VERSION ""

NS_ :

BS_:

BU_: ECU1 ECU2 ECU3

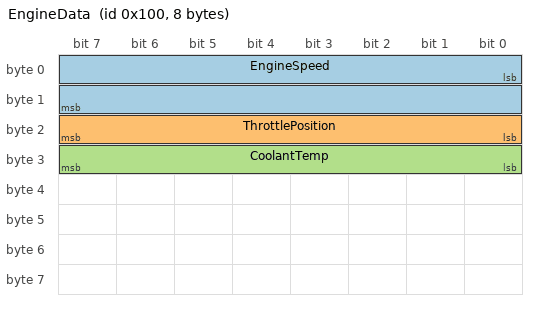
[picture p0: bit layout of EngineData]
BO_ 256 EngineData: 8 ECU1
 SG_ EngineSpeed : 0|16@1+ (1,0) [0|8000] "rpm" ECU2,ECU3
 SG_ ThrottlePosition : 16|8@1+ (0.5,0) [0|100] "%" ECU2
 SG_ CoolantTemp : 24|8@1- (1,-40) [-40|215] "degC" ECU2

BO_ 512 VehicleSpeed: 4 ECU2
 SG_ Speed : 0|16@1+ (0.01,0) [0|250] "km/h" ECU1,ECU3
 SG_ Odometer : 16|16@1+ (1,0) [0|65535] "km" ECU1

BO_ 768 GearStatus: 2 ECU3
 SG_ CurrentGear : 0|4@1+ (1,0) [0|8] "" ECU1,ECU2
 SG_ GearRequest : 4|4@1+ (1,0) [0|8] "" ECU1

CM_ SG_ 256 EngineSpeed "Engine rotational speed";
CM_ SG_ 256 ThrottlePosition "Throttle pedal position percentage";
CM_ SG_ 512 Speed "Vehicle speed in km/h";
